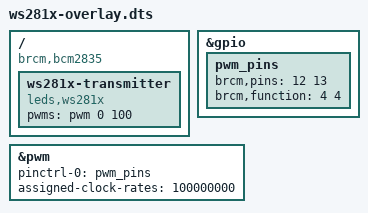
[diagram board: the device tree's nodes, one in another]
/dts-v1/;
/plugin/;

/*
Legal pin,function combinations for each channel:
  PWM0: 12,4(Alt0) 18,2(Alt5) 40,4(Alt0)			52,5(Alt1)
  PWM1: 13,4(Alt0) 19,2(Alt5) 41,4(Alt0) 45,4(Alt0) 53,5(Alt1)
*/

/ {
	compatible = "brcm,bcm2835";

	fragment@0 {
		target = <&gpio>;
		__overlay__ {
			pwm_pins: pwm_pins {
				brcm,pins = <12 13>;
				brcm,function = <4 4>; /* Alt0 */
			};
		};
	};

	fragment@1 {
		target = <&pwm>;
		frag1: __overlay__ {
			pinctrl-names = "default";
			pinctrl-0 = <&pwm_pins>;
			assigned-clock-rates = <100000000>;
			status = "okay";
		};
	};

	fragment@2 {
		target-path = "/";
		__overlay__ {
			ws281x-transmitter {
				compatible = "leds,ws281x";
				pwms = <&pwm 0 100>;
			};
		};
	};

	__overrides__ {
		pin   = <&pwm_pins>,"brcm,pins:0";
		pin2  = <&pwm_pins>,"brcm,pins:4";
		func  = <&pwm_pins>,"brcm,function:0";
		func2 = <&pwm_pins>,"brcm,function:4";
		clock = <&frag1>,"assigned-clock-rates:0";
	};
};
